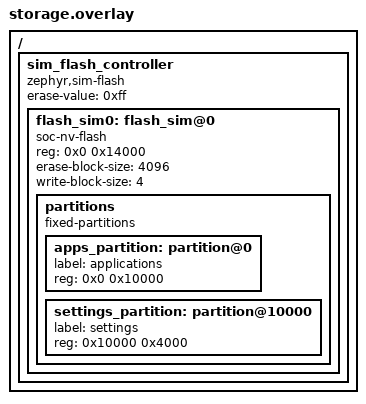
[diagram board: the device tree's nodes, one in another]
/* SPDX-License-Identifier: Apache-2.0 */
/* Small synthetic store for bounded capacity and atomic replacement checks. */
/ {
	sim_flash_controller {
		compatible = "zephyr,sim-flash";
		#address-cells = <1>;
		#size-cells = <1>;
		erase-value = <0xff>;
		flash_sim0: flash_sim@0 {
			compatible = "soc-nv-flash";
			reg = <0x0 0x14000>;
			erase-block-size = <4096>;
			write-block-size = <4>;
			partitions {
				compatible = "fixed-partitions";
				#address-cells = <1>;
				#size-cells = <1>;
				apps_partition: partition@0 {
					label = "applications";
					reg = <0x0 0x10000>;
				};
				settings_partition: partition@10000 {
					label = "settings";
					reg = <0x10000 0x4000>;
				};
			};
		};
	};
};
